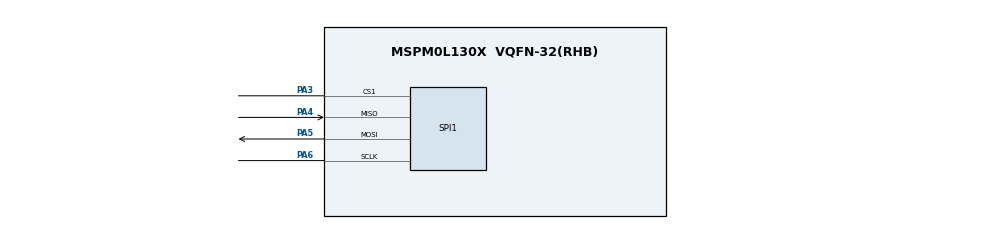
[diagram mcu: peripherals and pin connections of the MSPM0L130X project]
// @cliArgs --device "MSPM0L130X" --package "VQFN-32(RHB)" --part "Default"
// @cliArgs --board /ti/boards/LP_MSPM0L1306 --rtos nortos

/**
 * Import the modules used in this configuration.
 */
const SPI  = scripting.addModule("/ti/driverlib/SPI", {}, false);
const SPI1 = SPI.addInstance();

/**
 * Write custom configuration values to the imported modules.
 */
SPI1.$name                      = "SPI_0";
SPI1.mode                       = "PERIPHERAL";
SPI1.enabledInterrupts          = ["RX"];
SPI1.txFifoThreshold            = "DL_SPI_TX_FIFO_LEVEL_1_2_EMPTY";
SPI1.rxFifoThreshold            = "DL_SPI_RX_FIFO_LEVEL_1_4_FULL";
SPI1.peripheralChipSelect       = "1";
SPI1.peripheral.$assign         = "SPI0";
SPI1.peripheral.sclkPin.$assign = "PA6";
SPI1.peripheral.mosiPin.$assign = "PA5";
SPI1.peripheral.misoPin.$assign = "PA4";
SPI1.peripheral.cs1Pin.$assign  = "PA3";

const Board = scripting.addModule("/ti/driverlib/Board", {}, false);

const SYSCTL = scripting.addModule("/ti/driverlib/SYSCTL", {}, false);
SYSCTL.clockTreeEn = true;
